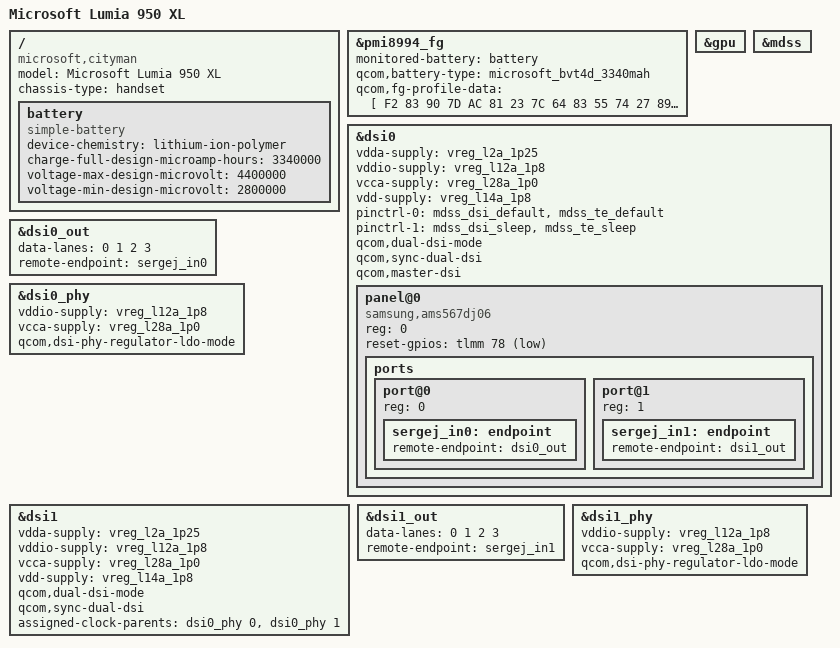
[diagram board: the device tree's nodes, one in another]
// SPDX-License-Identifier: BSD-3-Clause
/*
 * Copyright (c) 2020, Konrad Dybcio <konrad.dybcio@somainline.org>
 * Copyright (c) 2020, Gustave Monce <gustave.monce@outlook.com>
 */

/dts-v1/;

#include "msm8994.dtsi"
#include "msm8994-msft-lumia-octagon.dtsi"
#include <dt-bindings/interrupt-controller/irq.h>
#include <dt-bindings/gpio/gpio.h>

/ {
	model = "Microsoft Lumia 950 XL";
	compatible = "microsoft,cityman", "qcom,msm8994";
	chassis-type = "handset";

	battery: battery {
		compatible = "simple-battery";
		device-chemistry = "lithium-ion-polymer";
		charge-full-design-microamp-hours = <3340000>;
		voltage-max-design-microvolt = <4400000>;
		voltage-min-design-microvolt = <2800000>;
	};
};

&pmi8994_fg {
	monitored-battery = <&battery>;
	qcom,battery-type = "microsoft_bvt4d_3340mah";
	qcom,fg-profile-data = [
		F2 83 90 7D AC 81 23 7C
		64 83 55 74 27 89 0D 94
		38 82 29 98 0A B5 17 C0
		58 18 FF 83 9D 7D A8 81
		1A 7C 5D 83 FF 4E 84 82
		25 8E 17 82 B4 9A F7 BD
		59 CB 58 0E 71 0D 1F 5A
		14 70 B8 FE E4 45 49 37
		77 41 00 00 23 47 7A 32
		AF 31 00 00 00 00 00 00
		00 00 00 00 80 6B 23 6A
		EA 68 75 81 61 74 D9 62
		BE 6B 31 80 25 6E E6 59
		80 80 A6 C0 0F F0 60 3A
		5E A0 71 0C 28 00 FF 36
		F0 11 30 03 00 00 00 0C
	];
};

&gpu {
	status = "okay";
};

&mdss {
	status = "okay";
};

&dsi0 {
	status = "okay";
	#address-cells = <1>;
	#size-cells = <0>;

	vdda-supply = <&vreg_l2a_1p25>;
	vddio-supply = <&vreg_l12a_1p8>;
	vcca-supply = <&vreg_l28a_1p0>;
	vdd-supply = <&vreg_l14a_1p8>;

	pinctrl-names = "default", "sleep";
	pinctrl-0 = <&mdss_dsi_default &mdss_te_default>;
	pinctrl-1 = <&mdss_dsi_sleep &mdss_te_sleep>;

	qcom,dual-dsi-mode;
	qcom,sync-dual-dsi;
	qcom,master-dsi;

	panel@0 {
		compatible = "samsung,ams567dj06";
		reg = <0>;

		reset-gpios = <&tlmm 78 GPIO_ACTIVE_LOW>;

		ports {
			#address-cells = <1>;
			#size-cells = <0>;

			port@0 {
				reg = <0>;

				sergej_in0: endpoint {
					remote-endpoint = <&dsi0_out>;
				};
			};

			port@1 {
				reg = <1>;

				sergej_in1: endpoint {
					remote-endpoint = <&dsi1_out>;
				};
			};
		};
	};
};

&dsi0_out {
	data-lanes = <0 1 2 3>;
	remote-endpoint = <&sergej_in0>;
};

&dsi0_phy {
	status = "okay";

	vddio-supply = <&vreg_l12a_1p8>;
	vcca-supply = <&vreg_l28a_1p0>;

	qcom,dsi-phy-regulator-ldo-mode;
};

&dsi1 {
	status = "okay";

	vdda-supply = <&vreg_l2a_1p25>;
	vddio-supply = <&vreg_l12a_1p8>;
	vcca-supply = <&vreg_l28a_1p0>;
	vdd-supply = <&vreg_l14a_1p8>;

	qcom,dual-dsi-mode;
	qcom,sync-dual-dsi;

	assigned-clock-parents = <&dsi0_phy 0>, <&dsi0_phy 1>;
};

&dsi1_out {
	data-lanes = <0 1 2 3>;
	remote-endpoint = <&sergej_in1>;
};

&dsi1_phy {
	status = "okay";

	vddio-supply = <&vreg_l12a_1p8>;
	vcca-supply = <&vreg_l28a_1p0>;

	qcom,dsi-phy-regulator-ldo-mode;
};
